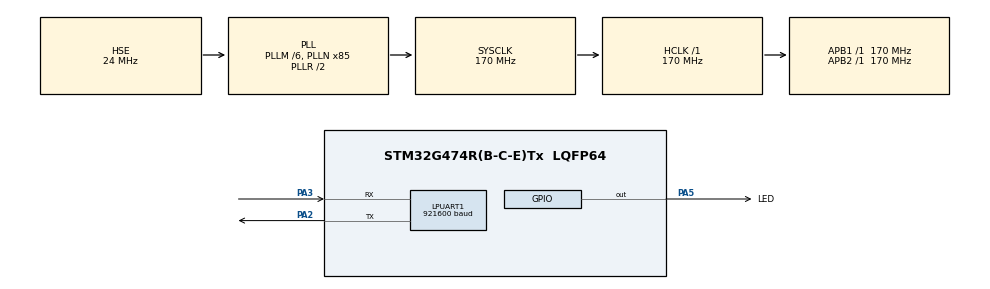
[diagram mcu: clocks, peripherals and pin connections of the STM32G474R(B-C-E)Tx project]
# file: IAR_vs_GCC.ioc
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LPUART1.BaudRate=921600
Mcu.Family=STM32G4
Mcu.Name=STM32G474R(B-C-E)Tx
Mcu.Package=LQFP64
NVIC.PriorityGroup=NVIC_PRIORITYGROUP_4
NVIC.TIM2_IRQn=true\:0\:0\:false\:false\:true\:true\:true
PA2.Mode=Asynchronous
PA2.Signal=LPUART1_TX
PA3.Mode=Asynchronous
PA3.Signal=LPUART1_RX
PA5.GPIO_Label=LED
PA5.Signal=GPIO_Output
PF0-OSC_IN.Mode=HSE-External-Oscillator
PF0-OSC_IN.Signal=RCC_OSC_IN
PF1-OSC_OUT.Mode=HSE-External-Oscillator
PF1-OSC_OUT.Signal=RCC_OSC_OUT
ProjectManager.HeapSize=0x2000
ProjectManager.StackSize=0x4000
ProjectManager.TargetToolchain=EWARM V8.32
RCC.ADC12Freq_Value=170000000
RCC.ADC345Freq_Value=170000000
RCC.AHBFreq_Value=170000000
RCC.APB1Freq_Value=170000000
RCC.APB1TimFreq_Value=170000000
RCC.APB2Freq_Value=170000000
RCC.APB2TimFreq_Value=170000000
RCC.CK48CLockSelection=RCC_USBCLKSOURCE_HSI48
RCC.CortexFreq_Value=170000000
RCC.EXTERNAL_CLOCK_VALUE=12288000
RCC.HCLKFreq_Value=170000000
RCC.HSE_VALUE=24000000
RCC.HSI48_VALUE=48000000
RCC.HSI_VALUE=16000000
RCC.LSE_VALUE=32768
RCC.PLLM=RCC_PLLM_DIV6
RCC.PLLN=85
RCC.PLLQ=RCC_PLLQ_DIV8
RCC.PLLSourceVirtual=RCC_PLLSOURCE_HSE
RCC.PREFETCH_ENABLE=1
RCC.SYSCLKFreq_VALUE=170000000
RCC.SYSCLKSource=RCC_SYSCLKSOURCE_PLLCLK
RCC.USBFreq_Value=48000000
RCC.VCOOutputFreq_Value=340000000
TIM2.PeriodNoDither=999
TIM2.Prescaler=169
VP_RNG_VS_RNG.Mode=RNG_Activate
VP_SYS_VS_DBSignals.Mode=DisableDeadBatterySignals
VP_TIM2_VS_ClockSourceINT.Mode=Internal
board=custom

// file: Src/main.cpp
/* USER CODE BEGIN Header */
/**
 ******************************************************************************
 * @file           : main.c
 * @brief          : Main program body
 ******************************************************************************
 * @attention
 *
 * <h2><center>&copy; Copyright (c) 2021 STMicroelectronics.
 * All rights reserved.</center></h2>
 *
 * This software component is licensed by ST under BSD 3-Clause license,
 * the "License"; You may not use this file except in compliance with the
 * License. You may obtain a copy of the License at:
 *                        opensource.org/licenses/BSD-3-Clause
 *
 ******************************************************************************
 */
/* USER CODE END Header */

#include "main.h"

/* USER CODE BEGIN Includes */
#include "calc.h"
/* USER CODE END Includes */

TIM_HandleTypeDef htim2;
UART_HandleTypeDef hlpuart1;
RNG_HandleTypeDef hrng;

void SystemClock_Config(void);
static void MX_GPIO_Init(void);
static void MX_TIM2_Init(void);
static void MX_LPUART1_UART_Init(void);
static void MX_RNG_Init(void);

int main(void)
{

	/* MCU Configuration--------------------------------------------------------*/

	/* Reset of all peripherals, Initializes the Flash interface and the Systick. */
	HAL_Init();

	/* Configure the system clock */
	SystemClock_Config();

	/* Initialize all configured peripherals */
	MX_GPIO_Init();
	MX_TIM2_Init();
	MX_LPUART1_UART_Init();
	MX_RNG_Init();
	/* USER CODE BEGIN 2 */

	// debug for optimization
	__HAL_UART_ENABLE(&hlpuart1);
	HAL_TIM_Base_Start_IT(&htim2);

	/* USER CODE END 2 */

	/* Infinite loop */
	while (1)
	{

		/* USER CODE BEGIN 3 */
		calc();

		HAL_GPIO_TogglePin(LED_GPIO_Port, LED_Pin);
		while (1)
			;
	}
	/* USER CODE END 3 */
}

void SystemClock_Config(void)
{
	RCC_OscInitTypeDef RCC_OscInitStruct = {0};
	RCC_ClkInitTypeDef RCC_ClkInitStruct = {0};
	RCC_PeriphCLKInitTypeDef PeriphClkInit = {0};

	/** Configure the main internal regulator output voltage
  */
	HAL_PWREx_ControlVoltageScaling(PWR_REGULATOR_VOLTAGE_SCALE1_BOOST);
	/** Initializes the CPU, AHB and APB busses clocks
  */
	RCC_OscInitStruct.OscillatorType = RCC_OSCILLATORTYPE_HSI48 | RCC_OSCILLATORTYPE_HSE;
	RCC_OscInitStruct.HSEState = RCC_HSE_ON;
	RCC_OscInitStruct.HSI48State = RCC_HSI48_ON;
	RCC_OscInitStruct.PLL.PLLState = RCC_PLL_ON;
	RCC_OscInitStruct.PLL.PLLSource = RCC_PLLSOURCE_HSE;
	RCC_OscInitStruct.PLL.PLLM = RCC_PLLM_DIV6;
	RCC_OscInitStruct.PLL.PLLN = 85;
	RCC_OscInitStruct.PLL.PLLP = RCC_PLLP_DIV2;
	RCC_OscInitStruct.PLL.PLLQ = RCC_PLLQ_DIV8;
	RCC_OscInitStruct.PLL.PLLR = RCC_PLLR_DIV2;
	if (HAL_RCC_OscConfig(&RCC_OscInitStruct) != HAL_OK)
	{
		Error_Handler();
	}
	/** Initializes the CPU, AHB and APB busses clocks
  */
	RCC_ClkInitStruct.ClockType = RCC_CLOCKTYPE_HCLK | RCC_CLOCKTYPE_SYSCLK | RCC_CLOCKTYPE_PCLK1 | RCC_CLOCKTYPE_PCLK2;
	RCC_ClkInitStruct.SYSCLKSource = RCC_SYSCLKSOURCE_PLLCLK;
	RCC_ClkInitStruct.AHBCLKDivider = RCC_SYSCLK_DIV1;
	RCC_ClkInitStruct.APB1CLKDivider = RCC_HCLK_DIV1;
	RCC_ClkInitStruct.APB2CLKDivider = RCC_HCLK_DIV1;

	if (HAL_RCC_ClockConfig(&RCC_ClkInitStruct, FLASH_LATENCY_8) != HAL_OK)
	{
		Error_Handler();
	}
	/** Initializes the peripherals clocks
  */
	PeriphClkInit.PeriphClockSelection = RCC_PERIPHCLK_LPUART1 | RCC_PERIPHCLK_RNG;
	PeriphClkInit.Lpuart1ClockSelection = RCC_LPUART1CLKSOURCE_PCLK1;
	PeriphClkInit.RngClockSelection = RCC_RNGCLKSOURCE_HSI48;
	if (HAL_RCCEx_PeriphCLKConfig(&PeriphClkInit) != HAL_OK)
	{
		Error_Handler();
	}
}
static void MX_LPUART1_UART_Init(void)
{

	hlpuart1.Instance = LPUART1;
	hlpuart1.Init.BaudRate = 921600;
	hlpuart1.Init.WordLength = UART_WORDLENGTH_8B;
	hlpuart1.Init.StopBits = UART_STOPBITS_1;
	hlpuart1.Init.Parity = UART_PARITY_NONE;
	hlpuart1.Init.Mode = UART_MODE_TX_RX;
	hlpuart1.Init.HwFlowCtl = UART_HWCONTROL_NONE;
	hlpuart1.Init.OneBitSampling = UART_ONE_BIT_SAMPLE_DISABLE;
	hlpuart1.AdvancedInit.AdvFeatureInit = UART_ADVFEATURE_NO_INIT;
	if (HAL_UART_Init(&hlpuart1) != HAL_OK)
	{
		Error_Handler();
	}
	if (HAL_UARTEx_SetTxFifoThreshold(&hlpuart1, UART_TXFIFO_THRESHOLD_1_8) != HAL_OK)
	{
		Error_Handler();
	}
	if (HAL_UARTEx_SetRxFifoThreshold(&hlpuart1, UART_RXFIFO_THRESHOLD_1_8) != HAL_OK)
	{
		Error_Handler();
	}
	if (HAL_UARTEx_DisableFifoMode(&hlpuart1) != HAL_OK)
	{
		Error_Handler();
	}
}

static void MX_RNG_Init(void)
{

	hrng.Instance = RNG;
	hrng.Init.ClockErrorDetection = RNG_CED_ENABLE;
	if (HAL_RNG_Init(&hrng) != HAL_OK)
	{
		Error_Handler();
	}
}

static void MX_TIM2_Init(void)
{

	TIM_ClockConfigTypeDef sClockSourceConfig = {0};
	TIM_MasterConfigTypeDef sMasterConfig = {0};

	htim2.Instance = TIM2;
	htim2.Init.Prescaler = 169;
	htim2.Init.CounterMode = TIM_COUNTERMODE_UP;
	htim2.Init.Period = 999;
	htim2.Init.ClockDivision = TIM_CLOCKDIVISION_DIV1;
	htim2.Init.AutoReloadPreload = TIM_AUTORELOAD_PRELOAD_DISABLE;
	if (HAL_TIM_Base_Init(&htim2) != HAL_OK)
	{
		Error_Handler();
	}
	sClockSourceConfig.ClockSource = TIM_CLOCKSOURCE_INTERNAL;
	if (HAL_TIM_ConfigClockSource(&htim2, &sClockSourceConfig) != HAL_OK)
	{
		Error_Handler();
	}
	sMasterConfig.MasterOutputTrigger = TIM_TRGO_RESET;
	sMasterConfig.MasterSlaveMode = TIM_MASTERSLAVEMODE_DISABLE;
	if (HAL_TIMEx_MasterConfigSynchronization(&htim2, &sMasterConfig) != HAL_OK)
	{
		Error_Handler();
	}
}
static void MX_GPIO_Init(void)
{
	GPIO_InitTypeDef GPIO_InitStruct = {0};

	/* GPIO Ports Clock Enable */
	__HAL_RCC_GPIOF_CLK_ENABLE();
	__HAL_RCC_GPIOA_CLK_ENABLE();

	/*Configure GPIO pin Output Level */
	HAL_GPIO_WritePin(LED_GPIO_Port, LED_Pin, GPIO_PIN_RESET);

	/*Configure GPIO pin : LED_Pin */
	GPIO_InitStruct.Pin = LED_Pin;
	GPIO_InitStruct.Mode = GPIO_MODE_OUTPUT_PP;
	GPIO_InitStruct.Pull = GPIO_NOPULL;
	GPIO_InitStruct.Speed = GPIO_SPEED_FREQ_LOW;
	HAL_GPIO_Init(LED_GPIO_Port, &GPIO_InitStruct);
}

/* USER CODE BEGIN 4 */

/* USER CODE BEGIN 4 */
/* USER CODE END 4 */

void Error_Handler(void)
{
}

/************************ (C) COPYRIGHT STMicroelectronics *****END OF FILE****/
